# CY8C5888LTI_LP097 register map
File version: 0.1
CY8C58LP
Registers are 8-bit, read-write, no defined reset value unless marked. A register's access mark holds for its fields unless they carry their own. Offsets are from the block's base; lines under a group give offsets from that group; [hi:lo] are bit positions; {n}, {i} and the like mark numbered series; 'fields as' and 'values as' point back to an identical list; <NAME> marks a mode.

## Memory map
0x00000000 Sample_Hold_1
0x00000000 ADC_DelSig_1
0x00000000 UART_1 — UART

## UART_1 — UART
Base 0x00000000
0x40006448 TX_UART_1_TX_DATA — TX Data Register
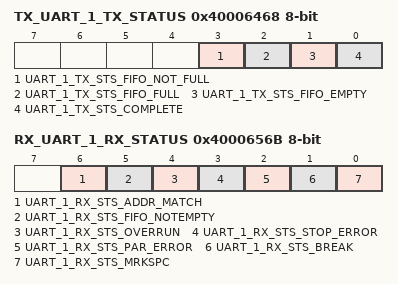
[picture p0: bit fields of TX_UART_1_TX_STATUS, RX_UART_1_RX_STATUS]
0x40006468 TX_UART_1_TX_STATUS — TX status register
  [3] UART_1_TX_STS_FIFO_NOT_FULL ro, [2] UART_1_TX_STS_FIFO_FULL ro, [1] UART_1_TX_STS_FIFO_EMPTY ro, [0] UART_1_TX_STS_COMPLETE ro
0x4000652B RX_UART_1_RX_ADDRESS1 — RX Address1 Register
0x4000653B RX_UART_1_RX_ADDRESS2 — RX Address2 Register
0x4000654B RX_UART_1_RX_DATA — RX Data Register
0x4000656B RX_UART_1_RX_STATUS — RX status register
  [6] UART_1_RX_STS_ADDR_MATCH ro, [5] UART_1_RX_STS_FIFO_NOTEMPTY ro, [4] UART_1_RX_STS_OVERRUN ro, [3] UART_1_RX_STS_STOP_ERROR ro, [2] UART_1_RX_STS_PAR_ERROR ro, [1] UART_1_RX_STS_BREAK ro, [0] UART_1_RX_STS_MRKSPC ro

## Sample_Hold_1
Base 0x00000000
0x400043A1 PM_ACT_CFG1 — Active Power Mode Configuration Register 1
  [3:0] en_clk_a — Enables subsystems during the active power mode
    {v}=en_clk_a_{v}_ (Enables clk_a {v}) (v=0..3)
0x400043A9 SC_PM_ACT_CFG — Active Power Mode Configuration Register 9
  [3:0] en_swcap — Enable switchcap block(s). Populated subsystems are counted from the LSB, for example bit 0 corresponds to switchcap block 0.
0x400043B1 PM_STBY_CFG1 — Standby Power Mode Configuration Register 1
  [3:0] en_clk_a — Enables subsystems during the standby power mode
    {v}=en_clk_a_{v}_ (Enables clk_a {v}) (v=0..3)
0x400043B9 SC_PM_STBY_CFG — Standby Power Mode Configuration Register 9
  fields as SC_PM_ACT_CFG
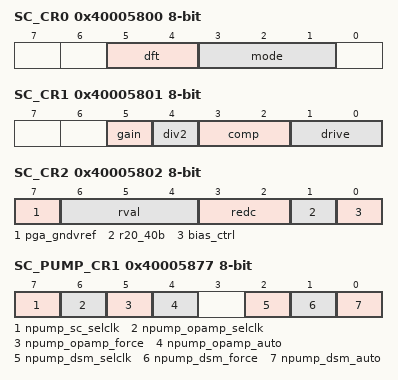
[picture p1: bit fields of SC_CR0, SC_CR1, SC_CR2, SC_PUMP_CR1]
0x40005800 SC_CR0 — Switched Capacitor Control Register 0
  [5:4] dft — Enables DFT mode for the switch cap block
    0=SC_DFT_NORMAL (Normal Operation); 1=SC_DFT_VBOOST (Vboost DFT); 2=SC_DFT_MODE_DEPENDENT (Mode Dependent); 3=SC_DFT_RESET (DFT Rreset)
  [3:1] mode — Configuration select for the SC block
    0=SC_MODE_NAKED_OPAMP (Naked Op-Amp); 1=SC_MODE_TIA (Transimpedance Amplifier (TIA)); 2=SC_MODE_CTMIXER (Continuous Time Mixer); 3=SC_MODE_NRZ_SH (Discrete Time Mixer - NRZ S/H); 4=SC_MODE_UNITY (Unity Gain Buffer); 5=SC_MODE_1ST_MOD (First Order Modulator); 6=SC_MODE_PGA (Programmable Gain Amplifier (PGA)); 7=SC_MODE_TRACKANDHOLD (Track and Hold)
0x40005801 SC_CR1 — Switched Capacitor Control Register 1
  [5] gain — Controls the ratio of the feedback cap for S/H Mixer mode
    0=GAIN_0DB (0 db); 1=GAIN_6DB (6 db)
  [4] div2 — When 0, the sample clock only needs to be half the desired sample frequency for S/H Mixer mode
    0=SC_DIV2_DISABLE (no frequency division); 1=SC_DIV2_ENABLE (SC CLK is divided by two)
  [3:2] comp — Selects between various compensation capacitor sizes
    0=SC_COMP_3P0PF (3.0pF); 1=SC_COMP_3P6PF (3.6pF); 2=SC_COMP_4P35PF (4.35pF); 3=SC_COMP_5P1PF (5.1pF)
  [1:0] drive — Selects between current settings (I_Load (uA)) in the output buffer
    0=I_LOAD_175UA (175 uA); 1=I_LOAD_260UA (260 uA); 2=I_LOAD_330UA (330 uA); 3=I_LOAD_400UA (400 uA)
0x40005802 SC_CR2 — Switched Capacitor Control Register 2
  [7] pga_gndvref — Programmable Gain Amplifier Application - Ground VREF
    0=SC_PGA_GNDVREF_DIS (VREF not grounded); 1=SC_PGA_GNDVREF_EN (VREF grounded)
  [6:4] rval — Programmable Gain Amplifier (PGA) and Transimpedance Amplifier (TIA): Feedback resistor (Rfb)
    0=SC_RVAL_20 (20 kOhm); 1=SC_RVAL_30 (30 kOhm); 2=SC_RVAL_40 (40 kOhm); 3=SC_RVAL_60 (60 kOhm); 4=SC_RVAL_120 (120 kOhm); 5=SC_RVAL_250 (250 kOhm); 6=SC_RVAL_500 (500 kOhm); 7=SC_RVAL_1000 (1 MegaOhm)
  [3:2] redc — Another stability control setting. Adjusts capactiance between amplifier output and first stage
    0=SC_REDC_00 (Varies depending on mode); 1=SC_REDC_01 (Varies depending on mode); 2=SC_REDC_10 (Varies depending on mode); 3=SC_REDC_11 (Varies depending on mode)
  [1] r20_40b — PGA Mode: input impedance (Rin), Mixer Mode: input and feedback impedance (Rmix)
    0=SC_R20_40B_40K (40kOhm); 1=SC_R20_40B_20K (20kOhm)
  [0] bias_ctrl — Toggles the bias current in the amplifier between normal and 1/2
    0=BIAS_1X (1x current reference reduces bandwidth to increase stability); 1=BIAS_2X (normal operation - 2x current reference to increase bandwidth)
0x40005877 SC_PUMP_CR1 — Pump Configuration Register 1
  [7] npump_sc_selclk — Switched Cap Negative Pump Clock Selection
    0=NPUMP_SC_SELCLK_EXTERNAL (External (DSI) clock selected); 1=NPUMP_SC_SELCLK_INTERNAL (Negative pump internal clock selected)
  [6] npump_opamp_selclk — Opamp Negative Pump Clock Selection
    0=NPUMP_OPAMP_SELCLK_EXTERNAL (External (DSI) clock selected); 1=NPUMP_OPAMP_SELCLK_INTERNAL (Negative pump internal clock selected)
  [5] npump_opamp_force — force pumping - if block enabled enable pump regardless of voltage state
  [4] npump_opamp_auto — enable autopumping - if block enabled pump when low voltage detected
  [2] npump_dsm_selclk — DSM Negative Pump Clock Selection
    0=NPUMP_DSM_SELCLK_EXTERNAL (External (DSI) clock selected); 1=NPUMP_DSM_SELCLK_INTERNAL (Negative pump internal clock selected)
  [1] npump_dsm_force — force pumping - if block enabled enable pump regardless of voltage state
  [0] npump_dsm_auto — enable autopumping - if block enabled pump when low voltage detected
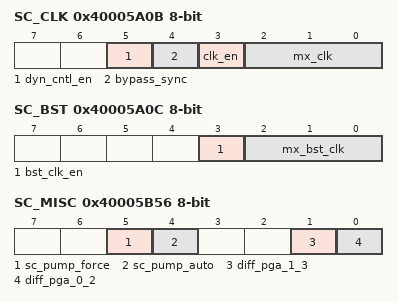
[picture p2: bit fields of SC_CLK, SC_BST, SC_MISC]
0x40005A0B SC_CLK — Switched Capacitor Clock Selection Register
  [5] dyn_cntl_en — Enable Dynamic Control (UDB generated clock source drives dynamic control)
    0=DYN_CNTL_DIS (Dynamic Control Disabled); 1=DYN_CNTL_EN (Dynamic Control Enabled)
  [4] bypass_sync — Bypass Synchronization
    0=Synchronization not bypassed; 1=Synchronization bypassed
  [3] clk_en — Clock gating control
    0=disable clock; 1=enable clock
  [2:0] mx_clk — Clock Selection
    {v}=Select clk_a{v} and clk_a{v}_dig (v=0..3); 4=Select UDB generated clock
0x40005A0C SC_BST — Switched Capacitor Boost Clock Selection Register
  [3] bst_clk_en — Clock gating control
    0=CLK_EN_0 (disable clock); 1=CLK_EN_1 (enable clock)
  [2:0] mx_bst_clk — Clock Selection
    {v}=MX_CLK_{v} (Select clk_a{v} and clk_a{v}_dig) (v=0..3); 4=MX_CLK_4 (Select UDB generated clock); 5=MX_CLK_5 (Reserved); 6=MX_CLK_6 (Reserved); 7=MX_CLK_7 (Reserved)
0x40005B56 SC_MISC — Switched Cap Miscellaneous Control Register
  [5] sc_pump_force — force pumping - if block enabled enable pump regardless of voltage state
  [4] sc_pump_auto — enable autopumping - if block enabled pump when low voltage detected
  [1] diff_pga_1_3 — Switched Cap Pair Connect for Differential Amplifier Applications
    0=SC_DIFF_PGA_DISABLED (Differential PGA pair connect disabled); 1=SC_DIFF_PGA_ENABLED (Differential PGA pair connect enabled)
  [0] diff_pga_0_2 — Switched Cap Pair Connect for Differential Amplifier Applications
    values as diff_pga_1_3
